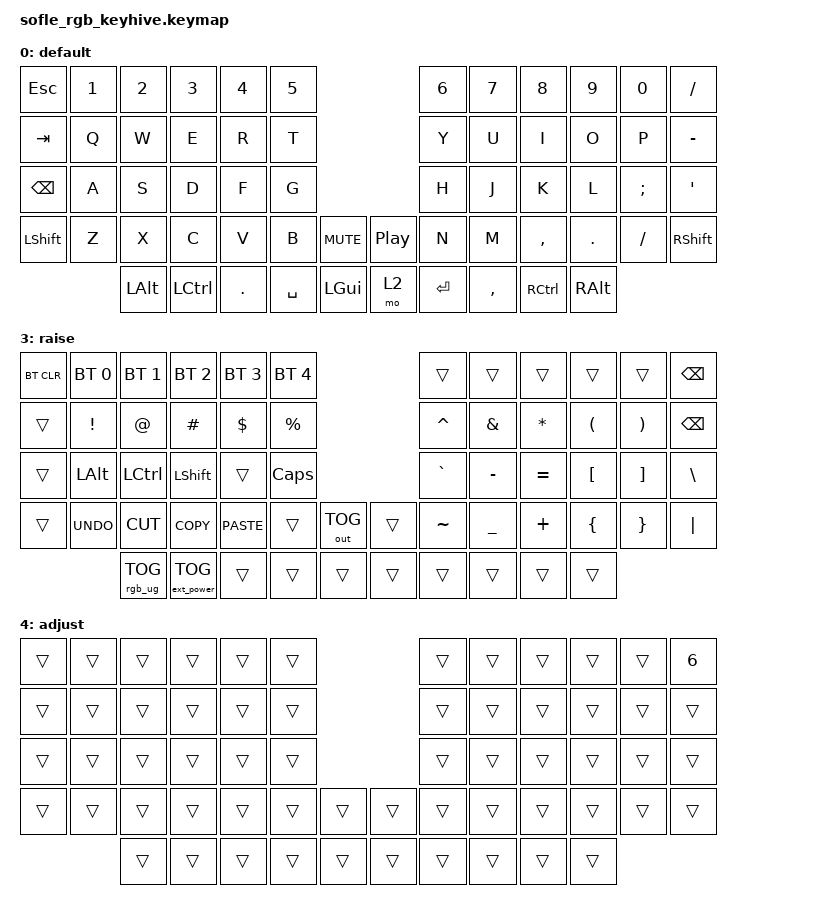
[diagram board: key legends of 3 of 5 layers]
/*
 * Copyright (c) 2020-2022 The ZMK Contributors
 *
 * SPDX-License-Identifier: MIT
 */

#include <behaviors.dtsi>
#include <dt-bindings/zmk/bt.h>
#include <dt-bindings/zmk/ext_power.h>
#include <dt-bindings/zmk/keys.h>
#include <dt-bindings/zmk/outputs.h>
#include <dt-bindings/zmk/rgb.h>

#define _DF  0 //  0 DEFAULT
#define _GM  1 //  1 GAMING
#define _LW  2 //  2 LOWER
#define _RE  3 //  3 RAISE
#define _AJ  4 //  4 ADJUST

&lt { quick-tap-ms = <180>; };

&mt { tapping-term-ms = <180>; };

/ {
    conditional_layers {
        compatible = "zmk,conditional-layers";

        adjust_layer {
            if-layers = <_LW _RE>;
            then-layer = <_AJ>;
        };
    };

    keymap {
        compatible = "zmk,keymap";

        default_layer {
            label = "default";
            bindings = <
&kp ESC    &kp N1  &kp N2    &kp N3     &kp N4      &kp N5                           &kp N6     &kp N7     &kp N8     &kp N9    &kp N0         &kp SLASH
&kp TAB    &kp Q   &kp W     &kp E      &kp R       &kp T                            &kp Y      &kp U      &kp I      &kp O     &kp P          &kp MINUS
&kp BSPC   &kp A   &kp S     &kp D      &kp F       &kp G                            &kp H      &kp J      &kp K      &kp L     &kp SEMICOLON  &kp SQT
&kp LSHFT  &kp Z   &kp X     &kp C      &kp V       &kp B      &kp C_MUTE  &kp C_PP  &kp N      &kp M      &kp COMMA  &kp DOT   &kp FSLH       &kp RSHFT
                   &kp LALT  &kp LCTRL  &kp PERIOD  &kp SPACE  &kp LGUI    &mo 2     &kp ENTER  &kp COMMA  &kp RCTRL  &kp RALT
            >;

            sensor-bindings = <&inc_dec_kp C_VOL_UP C_VOL_DN>;
        };

        game_layer {
            label = "game";
            bindings = <
&kp GRAVE      &kp DEL          &kp N2           &kp N3           &kp N4           &kp N5                                 &kp N6           &kp N7  &kp N8     &kp N9           &kp N0    &out OUT_BLE
&kp TAB        &kp Q            &rgb_ug RGB_EFR  &rgb_ug RGB_EFF  &reset           &kp T                                  &kp Y            &reset  &kp I      &rgb_ug RGB_TOG  &kp P     &kp BSLH
&mt LCTRL ESC  &rgb_ug RGB_SPI  &rgb_ug RGB_SAI  &kp D            &rgb_ug RGB_EFF  &kp G                                  &rgb_ug RGB_HUI  &kp J   &kp K      &kp L            &kp UP    &kp SQT
&kp LSHFT      &rgb_ug RGB_SPD  &rgb_ug RGB_SAD  &kp C            &kp V            &rgb_ug RGB_BRI  &kp C_MUTE  &kp C_PP  &rgb_ug RGB_HUD  &kp M   &kp COMMA  &kp LEFT         &kp DOWN  &kp RIGHT
                                &kp LGUI         &kp LALT         &kp E            &rgb_ug RGB_BRD  &lt 2 A
            >;

            sensor-bindings = <&inc_dec_kp C_VOL_UP C_VOL_DN &inc_dec_kp C_BRI_UP LS(C_BRI_DN)>;
        };

        lower_layer {
            label = "lower";
            bindings = <
&trans   &kp F1  &kp F2  &kp F3  &kp F4  &kp F5                  &kp F6       &kp F7  &kp F8  &kp F9  &kp F10       &kp F11
&trans   &kp N1  &kp N2  &kp N3  &kp N4  &kp N5                  &kp N6       &kp N7  &kp N8  &kp N9  &kp N0        &kp BSPC
&kp F11  &kp F1  &kp F2  &kp F3  &kp F4  &kp F5                  &kp KP_PLUS  &kp N4  &kp N5  &kp N6  &kp KP_ENTER  &kp KP_MULTIPLY
&kp F12  &kp F6  &kp F7  &kp F8  &kp F9  &kp F10  &to 1  &trans  &trans       &trans  &trans  &trans  &trans        &trans
                 &trans  &trans  &trans
            >;

            sensor-bindings = <&inc_dec_kp PG_UP PG_DN>;
        };

        raise_layer {
            label = "raise";
            bindings = <
&bt BT_CLR  &bt BT_SEL 0  &bt BT_SEL 1     &bt BT_SEL 2       &bt BT_SEL 3  &bt BT_SEL 4                        &trans     &trans     &trans     &trans    &trans    &kp BSPC
&trans      &kp EXCL      &kp AT           &kp HASH           &kp DLLR      &kp PRCNT                           &kp CARET  &kp AMPS   &kp ASTRK  &kp LPAR  &kp RPAR  &kp BSPC
&trans      &kp LALT      &kp LCTRL        &kp LSHFT          &trans        &kp CLCK                            &kp GRAVE  &kp MINUS  &kp EQUAL  &kp LBKT  &kp RBKT  &kp BSLH
&trans      &kp K_UNDO    &kp K_CUT        &kp K_COPY         &kp K_PASTE   &trans        &out OUT_TOG  &trans  &kp TILDE  &kp UNDER  &kp PLUS   &kp LBRC  &kp RBRC  &kp PIPE
                          &rgb_ug RGB_TOG  &ext_power EP_TOG  &trans        &trans        &trans        &trans  &trans     &trans     &trans     &trans
            >;

            sensor-bindings = <&inc_dec_kp PG_UP PG_DN>;
        };

        adjust_layer {
            label = "adjust";
            bindings = <
&trans  &trans  &trans  &trans  &trans  &trans                  &trans  &trans  &trans  &trans  &trans  &kp N6
&trans  &trans  &trans  &trans  &trans  &trans                  &trans  &trans  &trans  &trans  &trans  &trans
&trans  &trans  &trans  &trans  &trans  &trans                  &trans  &trans  &trans  &trans  &trans  &trans
&trans  &trans  &trans  &trans  &trans  &trans  &trans  &trans  &trans  &trans  &trans  &trans  &trans  &trans
                &trans  &trans  &trans  &trans  &trans  &trans  &trans  &trans  &trans  &trans
            >;

            sensor-bindings = <&inc_dec_kp PG_UP PG_DN>;
        };
    };
};
